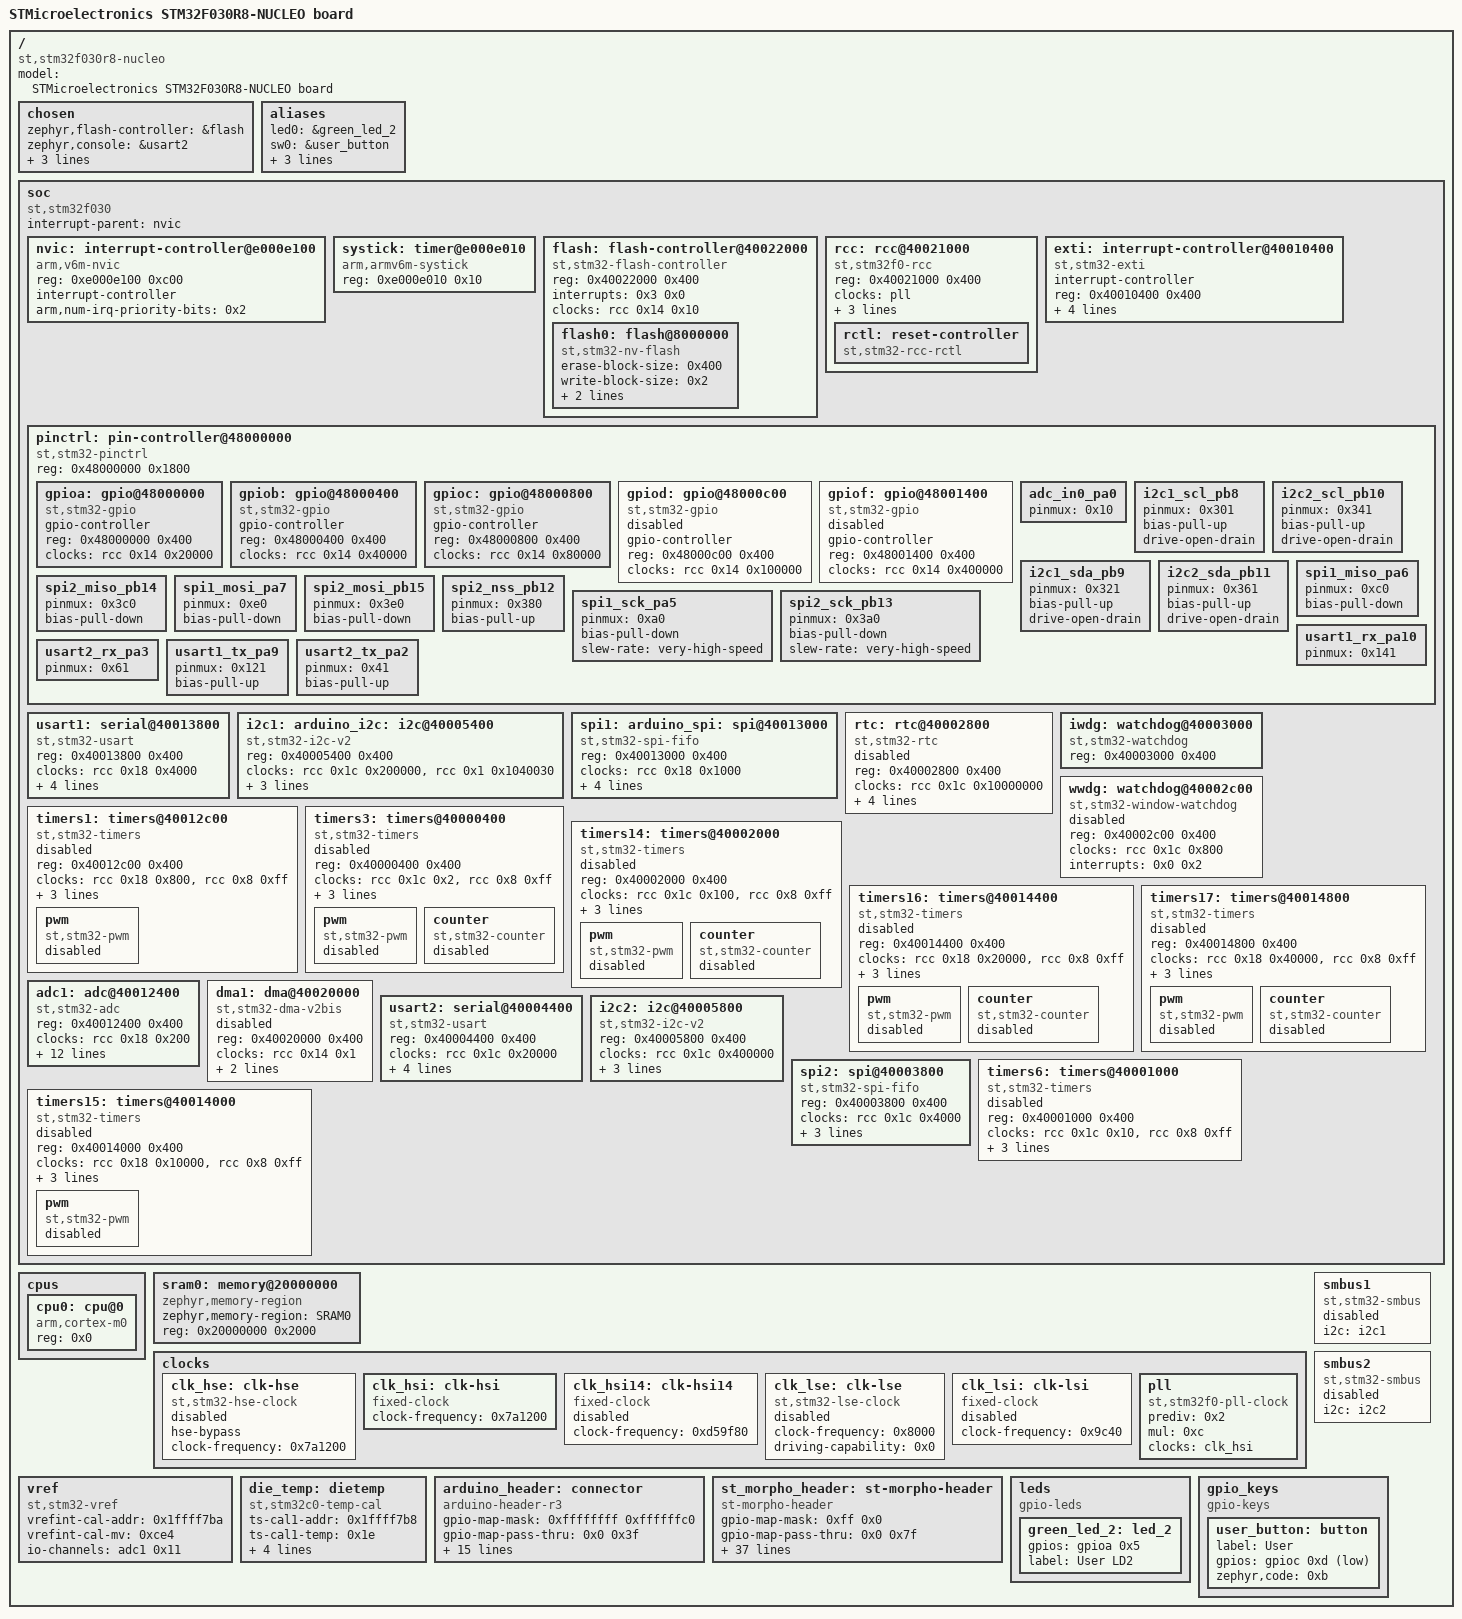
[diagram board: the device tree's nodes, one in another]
/dts-v1/;

/* node '/' defined in zephyr/dts/common/skeleton.dtsi:9 */
/ {
	#address-cells = < 0x1 >;                              /* in zephyr/dts/common/skeleton.dtsi:10 */
	#size-cells = < 0x1 >;                                 /* in zephyr/dts/common/skeleton.dtsi:11 */
	model = "STMicroelectronics STM32F030R8-NUCLEO board"; /* in zephyr/boards/st/nucleo_f030r8/nucleo_f030r8.dts:15 */
	compatible = "st,stm32f030r8-nucleo";                  /* in zephyr/boards/st/nucleo_f030r8/nucleo_f030r8.dts:16 */

	/* node '/chosen' defined in zephyr/dts/common/skeleton.dtsi:13 */
	chosen {
		zephyr,flash-controller = &flash; /* in zephyr/dts/arm/st/f0/stm32f0.dtsi:24 */
		zephyr,console = &usart2;         /* in zephyr/boards/st/nucleo_f030r8/nucleo_f030r8.dts:19 */
		zephyr,shell-uart = &usart2;      /* in zephyr/boards/st/nucleo_f030r8/nucleo_f030r8.dts:20 */
		zephyr,sram = &sram0;             /* in zephyr/boards/st/nucleo_f030r8/nucleo_f030r8.dts:21 */
		zephyr,flash = &flash0;           /* in zephyr/boards/st/nucleo_f030r8/nucleo_f030r8.dts:22 */
	};

	/* node '/aliases' defined in zephyr/dts/common/skeleton.dtsi:15 */
	aliases {
		led0 = &green_led_2;   /* in zephyr/boards/st/nucleo_f030r8/nucleo_f030r8.dts:45 */
		sw0 = &user_button;    /* in zephyr/boards/st/nucleo_f030r8/nucleo_f030r8.dts:46 */
		watchdog0 = &iwdg;     /* in zephyr/boards/st/nucleo_f030r8/nucleo_f030r8.dts:47 */
		die-temp0 = &die_temp; /* in zephyr/boards/st/nucleo_f030r8/nucleo_f030r8.dts:48 */
		volt-sensor0 = &vref;  /* in zephyr/boards/st/nucleo_f030r8/nucleo_f030r8.dts:49 */
	};

	/* node '/soc' defined in zephyr/dts/arm/armv6-m.dtsi:6 */
	soc {
		#address-cells = < 0x1 >;     /* in zephyr/dts/arm/armv6-m.dtsi:7 */
		#size-cells = < 0x1 >;        /* in zephyr/dts/arm/armv6-m.dtsi:8 */
		interrupt-parent = < &nvic >; /* in zephyr/dts/arm/armv6-m.dtsi:10 */
		ranges;                       /* in zephyr/dts/arm/armv6-m.dtsi:11 */
		compatible = "st,stm32f030",
		             "st,stm32f0",
		             "simple-bus";    /* in zephyr/dts/arm/st/f0/stm32f030.dtsi:11 */

		/* node '/soc/interrupt-controller@e000e100' defined in zephyr/dts/arm/armv6-m.dtsi:13 */
		nvic: interrupt-controller@e000e100 {
			#address-cells = < 0x1 >;            /* in zephyr/dts/arm/armv6-m.dtsi:14 */
			compatible = "arm,v6m-nvic";         /* in zephyr/dts/arm/armv6-m.dtsi:15 */
			reg = < 0xe000e100 0xc00 >;          /* in zephyr/dts/arm/armv6-m.dtsi:16 */
			interrupt-controller;                /* in zephyr/dts/arm/armv6-m.dtsi:17 */
			#interrupt-cells = < 0x2 >;          /* in zephyr/dts/arm/armv6-m.dtsi:18 */
			arm,num-irq-priority-bits = < 0x2 >; /* in zephyr/dts/arm/st/f0/stm32f0.dtsi:393 */
			phandle = < 0x1 >;                   /* in zephyr/dts/arm/armv6-m.dtsi:10 */
		};

		/* node '/soc/timer@e000e010' defined in zephyr/dts/arm/armv6-m.dtsi:21 */
		systick: timer@e000e010 {
			compatible = "arm,armv6m-systick"; /* in zephyr/dts/arm/armv6-m.dtsi:22 */
			reg = < 0xe000e010 0x10 >;         /* in zephyr/dts/arm/armv6-m.dtsi:23 */
		};

		/* node '/soc/flash-controller@40022000' defined in zephyr/dts/arm/st/f0/stm32f0.dtsi:87 */
		flash: flash-controller@40022000 {
			compatible = "st,stm32-flash-controller",
			             "st,stm32f1-flash-controller"; /* in zephyr/dts/arm/st/f0/stm32f0.dtsi:88 */
			reg = < 0x40022000 0x400 >;                 /* in zephyr/dts/arm/st/f0/stm32f0.dtsi:89 */
			interrupts = < 0x3 0x0 >;                   /* in zephyr/dts/arm/st/f0/stm32f0.dtsi:90 */
			clocks = < &rcc 0x14 0x10 >;                /* in zephyr/dts/arm/st/f0/stm32f0.dtsi:91 */
			#address-cells = < 0x1 >;                   /* in zephyr/dts/arm/st/f0/stm32f0.dtsi:93 */
			#size-cells = < 0x1 >;                      /* in zephyr/dts/arm/st/f0/stm32f0.dtsi:94 */

			/* node '/soc/flash-controller@40022000/flash@8000000' defined in zephyr/dts/arm/st/f0/stm32f0.dtsi:96 */
			flash0: flash@8000000 {
				compatible = "st,stm32-nv-flash",
				             "soc-nv-flash";      /* in zephyr/dts/arm/st/f0/stm32f0.dtsi:97 */
				erase-block-size = < 0x400 >;     /* in zephyr/dts/arm/st/f0/stm32f0.dtsi:98 */
				write-block-size = < 0x2 >;       /* in zephyr/dts/arm/st/f0/stm32f0.dtsi:99 */
				max-erase-time = < 0x28 >;        /* in zephyr/dts/arm/st/f0/stm32f0.dtsi:101 */
				reg = < 0x8000000 0x10000 >;      /* in zephyr/dts/arm/st/f0/stm32f030X8.dtsi:16 */
			};
		};

		/* node '/soc/rcc@40021000' defined in zephyr/dts/arm/st/f0/stm32f0.dtsi:105 */
		rcc: rcc@40021000 {
			compatible = "st,stm32f0-rcc";   /* in zephyr/dts/arm/st/f0/stm32f0.dtsi:106 */
			#clock-cells = < 0x2 >;          /* in zephyr/dts/arm/st/f0/stm32f0.dtsi:107 */
			reg = < 0x40021000 0x400 >;      /* in zephyr/dts/arm/st/f0/stm32f0.dtsi:108 */
			clocks = < &pll >;               /* in zephyr/boards/st/nucleo_f030r8/nucleo_f030r8.dts:67 */
			clock-frequency = < 0x2dc6c00 >; /* in zephyr/boards/st/nucleo_f030r8/nucleo_f030r8.dts:68 */
			ahb-prescaler = < 0x1 >;         /* in zephyr/boards/st/nucleo_f030r8/nucleo_f030r8.dts:69 */
			apb1-prescaler = < 0x1 >;        /* in zephyr/boards/st/nucleo_f030r8/nucleo_f030r8.dts:70 */
			phandle = < 0x2 >;               /* in zephyr/dts/arm/st/f0/stm32f0.dtsi:91 */

			/* node '/soc/rcc@40021000/reset-controller' defined in zephyr/dts/arm/st/f0/stm32f0.dtsi:110 */
			rctl: reset-controller {
				compatible = "st,stm32-rcc-rctl"; /* in zephyr/dts/arm/st/f0/stm32f0.dtsi:111 */
				#reset-cells = < 0x1 >;           /* in zephyr/dts/arm/st/f0/stm32f0.dtsi:112 */
				phandle = < 0x4 >;                /* in zephyr/dts/arm/st/f0/stm32f0.dtsi:180 */
			};
		};

		/* node '/soc/interrupt-controller@40010400' defined in zephyr/dts/arm/st/f0/stm32f0.dtsi:116 */
		exti: interrupt-controller@40010400 {
			compatible = "st,stm32-exti"; /* in zephyr/dts/arm/st/f0/stm32f0.dtsi:117 */
			interrupt-controller;         /* in zephyr/dts/arm/st/f0/stm32f0.dtsi:118 */
			#interrupt-cells = < 0x1 >;   /* in zephyr/dts/arm/st/f0/stm32f0.dtsi:119 */
			#address-cells = < 0x0 >;     /* in zephyr/dts/arm/st/f0/stm32f0.dtsi:120 */
			reg = < 0x40010400 0x400 >;   /* in zephyr/dts/arm/st/f0/stm32f0.dtsi:121 */
			clocks = < &rcc 0x18 0x1 >;   /* in zephyr/dts/arm/st/f0/stm32f0.dtsi:122 */
			num-lines = < 0x20 >;         /* in zephyr/dts/arm/st/f0/stm32f0.dtsi:123 */
			interrupts = < 0x5 0x0 >,
			             < 0x6 0x0 >,
			             < 0x7 0x0 >;     /* in zephyr/dts/arm/st/f0/stm32f0.dtsi:124 */
			interrupt-names = "line0-1",
			                  "line2-3",
			                  "line4-15"; /* in zephyr/dts/arm/st/f0/stm32f0.dtsi:125 */
			line-ranges = < 0x0 0x2 >,
			              < 0x2 0x2 >,
			              < 0x4 0xc >;    /* in zephyr/dts/arm/st/f0/stm32f0.dtsi:126 */
		};

		/* node '/soc/pin-controller@48000000' defined in zephyr/dts/arm/st/f0/stm32f0.dtsi:129 */
		pinctrl: pin-controller@48000000 {
			compatible = "st,stm32-pinctrl"; /* in zephyr/dts/arm/st/f0/stm32f0.dtsi:130 */
			#address-cells = < 0x1 >;        /* in zephyr/dts/arm/st/f0/stm32f0.dtsi:131 */
			#size-cells = < 0x1 >;           /* in zephyr/dts/arm/st/f0/stm32f0.dtsi:132 */
			reg = < 0x48000000 0x1800 >;     /* in zephyr/dts/arm/st/f0/stm32f0.dtsi:133 */

			/* node '/soc/pin-controller@48000000/gpio@48000000' defined in zephyr/dts/arm/st/f0/stm32f0.dtsi:135 */
			gpioa: gpio@48000000 {
				compatible = "st,stm32-gpio";   /* in zephyr/dts/arm/st/f0/stm32f0.dtsi:136 */
				gpio-controller;                /* in zephyr/dts/arm/st/f0/stm32f0.dtsi:137 */
				#gpio-cells = < 0x2 >;          /* in zephyr/dts/arm/st/f0/stm32f0.dtsi:138 */
				reg = < 0x48000000 0x400 >;     /* in zephyr/dts/arm/st/f0/stm32f0.dtsi:139 */
				clocks = < &rcc 0x14 0x20000 >; /* in zephyr/dts/arm/st/f0/stm32f0.dtsi:140 */
				phandle = < 0x1a >;             /* in zephyr/boards/st/nucleo_f030r8/arduino_r3_connector.dtsi:15 */
			};

			/* node '/soc/pin-controller@48000000/gpio@48000400' defined in zephyr/dts/arm/st/f0/stm32f0.dtsi:143 */
			gpiob: gpio@48000400 {
				compatible = "st,stm32-gpio";   /* in zephyr/dts/arm/st/f0/stm32f0.dtsi:144 */
				gpio-controller;                /* in zephyr/dts/arm/st/f0/stm32f0.dtsi:145 */
				#gpio-cells = < 0x2 >;          /* in zephyr/dts/arm/st/f0/stm32f0.dtsi:146 */
				reg = < 0x48000400 0x400 >;     /* in zephyr/dts/arm/st/f0/stm32f0.dtsi:147 */
				clocks = < &rcc 0x14 0x40000 >; /* in zephyr/dts/arm/st/f0/stm32f0.dtsi:148 */
				phandle = < 0xc >;              /* in zephyr/boards/st/nucleo_f030r8/nucleo_f030r8.dts:114 */
			};

			/* node '/soc/pin-controller@48000000/gpio@48000800' defined in zephyr/dts/arm/st/f0/stm32f0.dtsi:151 */
			gpioc: gpio@48000800 {
				compatible = "st,stm32-gpio";   /* in zephyr/dts/arm/st/f0/stm32f0.dtsi:152 */
				gpio-controller;                /* in zephyr/dts/arm/st/f0/stm32f0.dtsi:153 */
				#gpio-cells = < 0x2 >;          /* in zephyr/dts/arm/st/f0/stm32f0.dtsi:154 */
				reg = < 0x48000800 0x400 >;     /* in zephyr/dts/arm/st/f0/stm32f0.dtsi:155 */
				clocks = < &rcc 0x14 0x80000 >; /* in zephyr/dts/arm/st/f0/stm32f0.dtsi:156 */
				phandle = < 0x1b >;             /* in zephyr/boards/st/nucleo_f030r8/arduino_r3_connector.dtsi:15 */
			};

			/* node '/soc/pin-controller@48000000/gpio@48000c00' defined in zephyr/dts/arm/st/f0/stm32f0.dtsi:159 */
			gpiod: gpio@48000c00 {
				compatible = "st,stm32-gpio";    /* in zephyr/dts/arm/st/f0/stm32f0.dtsi:160 */
				gpio-controller;                 /* in zephyr/dts/arm/st/f0/stm32f0.dtsi:161 */
				#gpio-cells = < 0x2 >;           /* in zephyr/dts/arm/st/f0/stm32f0.dtsi:162 */
				reg = < 0x48000c00 0x400 >;      /* in zephyr/dts/arm/st/f0/stm32f0.dtsi:163 */
				clocks = < &rcc 0x14 0x100000 >; /* in zephyr/dts/arm/st/f0/stm32f0.dtsi:164 */
				status = "disabled";             /* in zephyr/boards/st/nucleo_f030r8/nucleo_f030r8.dts:76 */
				phandle = < 0x1c >;              /* in zephyr/boards/st/nucleo_f030r8/st_morpho_connector.dtsi:15 */
			};

			/* node '/soc/pin-controller@48000000/gpio@48001400' defined in zephyr/dts/arm/st/f0/stm32f0.dtsi:167 */
			gpiof: gpio@48001400 {
				compatible = "st,stm32-gpio";    /* in zephyr/dts/arm/st/f0/stm32f0.dtsi:168 */
				gpio-controller;                 /* in zephyr/dts/arm/st/f0/stm32f0.dtsi:169 */
				#gpio-cells = < 0x2 >;           /* in zephyr/dts/arm/st/f0/stm32f0.dtsi:170 */
				reg = < 0x48001400 0x400 >;      /* in zephyr/dts/arm/st/f0/stm32f0.dtsi:171 */
				clocks = < &rcc 0x14 0x400000 >; /* in zephyr/dts/arm/st/f0/stm32f0.dtsi:172 */
				status = "disabled";             /* in zephyr/boards/st/nucleo_f030r8/nucleo_f030r8.dts:80 */
				phandle = < 0x1d >;              /* in zephyr/boards/st/nucleo_f030r8/st_morpho_connector.dtsi:15 */
			};

			/* node '/soc/pin-controller@48000000/adc_in0_pa0' defined in modules/hal/stm32/dts/st/f0/stm32f030r8tx-pinctrl.dtsi:15 */
			adc_in0_pa0: adc_in0_pa0 {
				pinmux = < 0x10 >; /* in modules/hal/stm32/dts/st/f0/stm32f030r8tx-pinctrl.dtsi:16 */
				phandle = < 0xd >; /* in zephyr/boards/st/nucleo_f030r8/nucleo_f030r8.dts:126 */
			};

			/* node '/soc/pin-controller@48000000/i2c1_scl_pb8' defined in modules/hal/stm32/dts/st/f0/stm32f030r8tx-pinctrl.dtsi:309 */
			i2c1_scl_pb8: i2c1_scl_pb8 {
				pinmux = < 0x301 >; /* in modules/hal/stm32/dts/st/f0/stm32f030r8tx-pinctrl.dtsi:310 */
				bias-pull-up;       /* in modules/hal/stm32/dts/st/f0/stm32f030r8tx-pinctrl.dtsi:311 */
				drive-open-drain;   /* in modules/hal/stm32/dts/st/f0/stm32f030r8tx-pinctrl.dtsi:312 */
				phandle = < 0x7 >;  /* in zephyr/boards/st/nucleo_f030r8/nucleo_f030r8.dts:98 */
			};

			/* node '/soc/pin-controller@48000000/i2c2_scl_pb10' defined in modules/hal/stm32/dts/st/f0/stm32f030r8tx-pinctrl.dtsi:315 */
			i2c2_scl_pb10: i2c2_scl_pb10 {
				pinmux = < 0x341 >; /* in modules/hal/stm32/dts/st/f0/stm32f030r8tx-pinctrl.dtsi:316 */
				bias-pull-up;       /* in modules/hal/stm32/dts/st/f0/stm32f030r8tx-pinctrl.dtsi:317 */
				drive-open-drain;   /* in modules/hal/stm32/dts/st/f0/stm32f030r8tx-pinctrl.dtsi:318 */
				phandle = < 0x10 >; /* in zephyr/boards/st/nucleo_f030r8/nucleo_f030r8.dts:105 */
			};

			/* node '/soc/pin-controller@48000000/i2c1_sda_pb9' defined in modules/hal/stm32/dts/st/f0/stm32f030r8tx-pinctrl.dtsi:335 */
			i2c1_sda_pb9: i2c1_sda_pb9 {
				pinmux = < 0x321 >; /* in modules/hal/stm32/dts/st/f0/stm32f030r8tx-pinctrl.dtsi:336 */
				bias-pull-up;       /* in modules/hal/stm32/dts/st/f0/stm32f030r8tx-pinctrl.dtsi:337 */
				drive-open-drain;   /* in modules/hal/stm32/dts/st/f0/stm32f030r8tx-pinctrl.dtsi:338 */
				phandle = < 0x8 >;  /* in zephyr/boards/st/nucleo_f030r8/nucleo_f030r8.dts:98 */
			};

			/* node '/soc/pin-controller@48000000/i2c2_sda_pb11' defined in modules/hal/stm32/dts/st/f0/stm32f030r8tx-pinctrl.dtsi:341 */
			i2c2_sda_pb11: i2c2_sda_pb11 {
				pinmux = < 0x361 >; /* in modules/hal/stm32/dts/st/f0/stm32f030r8tx-pinctrl.dtsi:342 */
				bias-pull-up;       /* in modules/hal/stm32/dts/st/f0/stm32f030r8tx-pinctrl.dtsi:343 */
				drive-open-drain;   /* in modules/hal/stm32/dts/st/f0/stm32f030r8tx-pinctrl.dtsi:344 */
				phandle = < 0x11 >; /* in zephyr/boards/st/nucleo_f030r8/nucleo_f030r8.dts:105 */
			};

			/* node '/soc/pin-controller@48000000/spi1_miso_pa6' defined in modules/hal/stm32/dts/st/f0/stm32f030r8tx-pinctrl.dtsi:379 */
			spi1_miso_pa6: spi1_miso_pa6 {
				pinmux = < 0xc0 >; /* in modules/hal/stm32/dts/st/f0/stm32f030r8tx-pinctrl.dtsi:380 */
				bias-pull-down;    /* in modules/hal/stm32/dts/st/f0/stm32f030r8tx-pinctrl.dtsi:381 */
				phandle = < 0xa >; /* in zephyr/boards/st/nucleo_f030r8/nucleo_f030r8.dts:112 */
			};

			/* node '/soc/pin-controller@48000000/spi2_miso_pb14' defined in modules/hal/stm32/dts/st/f0/stm32f030r8tx-pinctrl.dtsi:389 */
			spi2_miso_pb14: spi2_miso_pb14 {
				pinmux = < 0x3c0 >; /* in modules/hal/stm32/dts/st/f0/stm32f030r8tx-pinctrl.dtsi:390 */
				bias-pull-down;     /* in modules/hal/stm32/dts/st/f0/stm32f030r8tx-pinctrl.dtsi:391 */
				phandle = < 0x14 >; /* in zephyr/boards/st/nucleo_f030r8/nucleo_f030r8.dts:119 */
			};

			/* node '/soc/pin-controller@48000000/spi1_mosi_pa7' defined in modules/hal/stm32/dts/st/f0/stm32f030r8tx-pinctrl.dtsi:396 */
			spi1_mosi_pa7: spi1_mosi_pa7 {
				pinmux = < 0xe0 >; /* in modules/hal/stm32/dts/st/f0/stm32f030r8tx-pinctrl.dtsi:397 */
				bias-pull-down;    /* in modules/hal/stm32/dts/st/f0/stm32f030r8tx-pinctrl.dtsi:398 */
				phandle = < 0xb >; /* in zephyr/boards/st/nucleo_f030r8/nucleo_f030r8.dts:112 */
			};

			/* node '/soc/pin-controller@48000000/spi2_mosi_pb15' defined in modules/hal/stm32/dts/st/f0/stm32f030r8tx-pinctrl.dtsi:406 */
			spi2_mosi_pb15: spi2_mosi_pb15 {
				pinmux = < 0x3e0 >; /* in modules/hal/stm32/dts/st/f0/stm32f030r8tx-pinctrl.dtsi:407 */
				bias-pull-down;     /* in modules/hal/stm32/dts/st/f0/stm32f030r8tx-pinctrl.dtsi:408 */
				phandle = < 0x15 >; /* in zephyr/boards/st/nucleo_f030r8/nucleo_f030r8.dts:119 */
			};

			/* node '/soc/pin-controller@48000000/spi2_nss_pb12' defined in modules/hal/stm32/dts/st/f0/stm32f030r8tx-pinctrl.dtsi:423 */
			spi2_nss_pb12: spi2_nss_pb12 {
				pinmux = < 0x380 >; /* in modules/hal/stm32/dts/st/f0/stm32f030r8tx-pinctrl.dtsi:424 */
				bias-pull-up;       /* in modules/hal/stm32/dts/st/f0/stm32f030r8tx-pinctrl.dtsi:425 */
				phandle = < 0x12 >; /* in zephyr/boards/st/nucleo_f030r8/nucleo_f030r8.dts:119 */
			};

			/* node '/soc/pin-controller@48000000/spi1_sck_pa5' defined in modules/hal/stm32/dts/st/f0/stm32f030r8tx-pinctrl.dtsi:430 */
			spi1_sck_pa5: spi1_sck_pa5 {
				pinmux = < 0xa0 >;             /* in modules/hal/stm32/dts/st/f0/stm32f030r8tx-pinctrl.dtsi:431 */
				bias-pull-down;                /* in modules/hal/stm32/dts/st/f0/stm32f030r8tx-pinctrl.dtsi:432 */
				slew-rate = "very-high-speed"; /* in modules/hal/stm32/dts/st/f0/stm32f030r8tx-pinctrl.dtsi:433 */
				phandle = < 0x9 >;             /* in zephyr/boards/st/nucleo_f030r8/nucleo_f030r8.dts:112 */
			};

			/* node '/soc/pin-controller@48000000/spi2_sck_pb13' defined in modules/hal/stm32/dts/st/f0/stm32f030r8tx-pinctrl.dtsi:442 */
			spi2_sck_pb13: spi2_sck_pb13 {
				pinmux = < 0x3a0 >;            /* in modules/hal/stm32/dts/st/f0/stm32f030r8tx-pinctrl.dtsi:443 */
				bias-pull-down;                /* in modules/hal/stm32/dts/st/f0/stm32f030r8tx-pinctrl.dtsi:444 */
				slew-rate = "very-high-speed"; /* in modules/hal/stm32/dts/st/f0/stm32f030r8tx-pinctrl.dtsi:445 */
				phandle = < 0x13 >;            /* in zephyr/boards/st/nucleo_f030r8/nucleo_f030r8.dts:119 */
			};

			/* node '/soc/pin-controller@48000000/usart1_rx_pa10' defined in modules/hal/stm32/dts/st/f0/stm32f030r8tx-pinctrl.dtsi:646 */
			usart1_rx_pa10: usart1_rx_pa10 {
				pinmux = < 0x141 >; /* in modules/hal/stm32/dts/st/f0/stm32f030r8tx-pinctrl.dtsi:647 */
				phandle = < 0x6 >;  /* in zephyr/boards/st/nucleo_f030r8/nucleo_f030r8.dts:84 */
			};

			/* node '/soc/pin-controller@48000000/usart2_rx_pa3' defined in modules/hal/stm32/dts/st/f0/stm32f030r8tx-pinctrl.dtsi:654 */
			usart2_rx_pa3: usart2_rx_pa3 {
				pinmux = < 0x61 >; /* in modules/hal/stm32/dts/st/f0/stm32f030r8tx-pinctrl.dtsi:655 */
				phandle = < 0xf >; /* in zephyr/boards/st/nucleo_f030r8/nucleo_f030r8.dts:91 */
			};

			/* node '/soc/pin-controller@48000000/usart1_tx_pa9' defined in modules/hal/stm32/dts/st/f0/stm32f030r8tx-pinctrl.dtsi:664 */
			usart1_tx_pa9: usart1_tx_pa9 {
				pinmux = < 0x121 >; /* in modules/hal/stm32/dts/st/f0/stm32f030r8tx-pinctrl.dtsi:665 */
				bias-pull-up;       /* in modules/hal/stm32/dts/st/f0/stm32f030r8tx-pinctrl.dtsi:666 */
				phandle = < 0x5 >;  /* in zephyr/boards/st/nucleo_f030r8/nucleo_f030r8.dts:84 */
			};

			/* node '/soc/pin-controller@48000000/usart2_tx_pa2' defined in modules/hal/stm32/dts/st/f0/stm32f030r8tx-pinctrl.dtsi:674 */
			usart2_tx_pa2: usart2_tx_pa2 {
				pinmux = < 0x41 >; /* in modules/hal/stm32/dts/st/f0/stm32f030r8tx-pinctrl.dtsi:675 */
				bias-pull-up;      /* in modules/hal/stm32/dts/st/f0/stm32f030r8tx-pinctrl.dtsi:676 */
				phandle = < 0xe >; /* in zephyr/boards/st/nucleo_f030r8/nucleo_f030r8.dts:91 */
			};
		};

		/* node '/soc/serial@40013800' defined in zephyr/dts/arm/st/f0/stm32f0.dtsi:176 */
		usart1: serial@40013800 {
			compatible = "st,stm32-usart",
			             "st,stm32-uart";                   /* in zephyr/dts/arm/st/f0/stm32f0.dtsi:177 */
			reg = < 0x40013800 0x400 >;                     /* in zephyr/dts/arm/st/f0/stm32f0.dtsi:178 */
			clocks = < &rcc 0x18 0x4000 >;                  /* in zephyr/dts/arm/st/f0/stm32f0.dtsi:179 */
			resets = < &rctl 0x18e >;                       /* in zephyr/dts/arm/st/f0/stm32f0.dtsi:180 */
			interrupts = < 0x1b 0x0 >;                      /* in zephyr/dts/arm/st/f0/stm32f0.dtsi:181 */
			pinctrl-0 = < &usart1_tx_pa9 &usart1_rx_pa10 >; /* in zephyr/boards/st/nucleo_f030r8/nucleo_f030r8.dts:84 */
			pinctrl-names = "default";                      /* in zephyr/boards/st/nucleo_f030r8/nucleo_f030r8.dts:85 */
			current-speed = < 0x1c200 >;                    /* in zephyr/boards/st/nucleo_f030r8/nucleo_f030r8.dts:86 */
			status = "okay";                                /* in zephyr/boards/st/nucleo_f030r8/nucleo_f030r8.dts:87 */
		};

		/* node '/soc/i2c@40005400' defined in zephyr/dts/arm/st/f0/stm32f0.dtsi:185 */
		i2c1: arduino_i2c: i2c@40005400 {
			compatible = "st,stm32-i2c-v2";              /* in zephyr/dts/arm/st/f0/stm32f0.dtsi:186 */
			#address-cells = < 0x1 >;                    /* in zephyr/dts/arm/st/f0/stm32f0.dtsi:188 */
			#size-cells = < 0x0 >;                       /* in zephyr/dts/arm/st/f0/stm32f0.dtsi:189 */
			reg = < 0x40005400 0x400 >;                  /* in zephyr/dts/arm/st/f0/stm32f0.dtsi:190 */
			clocks = < &rcc 0x1c 0x200000 >,
			         < &rcc 0x1 0x1040030 >;             /* in zephyr/dts/arm/st/f0/stm32f0.dtsi:191 */
			interrupts = < 0x17 0x0 >;                   /* in zephyr/dts/arm/st/f0/stm32f0.dtsi:196 */
			interrupt-names = "combined";                /* in zephyr/dts/arm/st/f0/stm32f0.dtsi:197 */
			pinctrl-0 = < &i2c1_scl_pb8 &i2c1_sda_pb9 >; /* in zephyr/boards/st/nucleo_f030r8/nucleo_f030r8.dts:98 */
			pinctrl-names = "default";                   /* in zephyr/boards/st/nucleo_f030r8/nucleo_f030r8.dts:99 */
			status = "okay";                             /* in zephyr/boards/st/nucleo_f030r8/nucleo_f030r8.dts:100 */
			clock-frequency = < 0x61a80 >;               /* in zephyr/boards/st/nucleo_f030r8/nucleo_f030r8.dts:101 */
			phandle = < 0x18 >;                          /* in zephyr/dts/arm/st/f0/stm32f0.dtsi:387 */
		};

		/* node '/soc/spi@40013000' defined in zephyr/dts/arm/st/f0/stm32f0.dtsi:201 */
		spi1: arduino_spi: spi@40013000 {
			compatible = "st,stm32-spi-fifo",
			             "st,stm32-spi";                                 /* in zephyr/dts/arm/st/f0/stm32f0.dtsi:202 */
			#address-cells = < 0x1 >;                                    /* in zephyr/dts/arm/st/f0/stm32f0.dtsi:203 */
			#size-cells = < 0x0 >;                                       /* in zephyr/dts/arm/st/f0/stm32f0.dtsi:204 */
			reg = < 0x40013000 0x400 >;                                  /* in zephyr/dts/arm/st/f0/stm32f0.dtsi:205 */
			clocks = < &rcc 0x18 0x1000 >;                               /* in zephyr/dts/arm/st/f0/stm32f0.dtsi:206 */
			interrupts = < 0x19 0x3 >;                                   /* in zephyr/dts/arm/st/f0/stm32f0.dtsi:207 */
			pinctrl-0 = < &spi1_sck_pa5 &spi1_miso_pa6 &spi1_mosi_pa7 >; /* in zephyr/boards/st/nucleo_f030r8/nucleo_f030r8.dts:112 */
			pinctrl-names = "default";                                   /* in zephyr/boards/st/nucleo_f030r8/nucleo_f030r8.dts:113 */
			cs-gpios = < &gpiob 0x6 0x11 >;                              /* in zephyr/boards/st/nucleo_f030r8/nucleo_f030r8.dts:114 */
			status = "okay";                                             /* in zephyr/boards/st/nucleo_f030r8/nucleo_f030r8.dts:115 */
		};

		/* node '/soc/rtc@40002800' defined in zephyr/dts/arm/st/f0/stm32f0.dtsi:211 */
		rtc: rtc@40002800 {
			compatible = "st,stm32-rtc";       /* in zephyr/dts/arm/st/f0/stm32f0.dtsi:212 */
			reg = < 0x40002800 0x400 >;        /* in zephyr/dts/arm/st/f0/stm32f0.dtsi:213 */
			clocks = < &rcc 0x1c 0x10000000 >; /* in zephyr/dts/arm/st/f0/stm32f0.dtsi:214 */
			interrupts = < 0x2 0x0 >;          /* in zephyr/dts/arm/st/f0/stm32f0.dtsi:215 */
			prescaler = < 0x8000 >;            /* in zephyr/dts/arm/st/f0/stm32f0.dtsi:216 */
			alarms-count = < 0x1 >;            /* in zephyr/dts/arm/st/f0/stm32f0.dtsi:217 */
			alrm-exti-line = < 0x11 >;         /* in zephyr/dts/arm/st/f0/stm32f0.dtsi:218 */
			status = "disabled";               /* in zephyr/dts/arm/st/f0/stm32f0.dtsi:219 */
		};

		/* node '/soc/watchdog@40003000' defined in zephyr/dts/arm/st/f0/stm32f0.dtsi:222 */
		iwdg: watchdog@40003000 {
			compatible = "st,stm32-watchdog"; /* in zephyr/dts/arm/st/f0/stm32f0.dtsi:223 */
			reg = < 0x40003000 0x400 >;       /* in zephyr/dts/arm/st/f0/stm32f0.dtsi:224 */
			status = "okay";                  /* in zephyr/boards/st/nucleo_f030r8/nucleo_f030r8.dts:134 */
		};

		/* node '/soc/watchdog@40002c00' defined in zephyr/dts/arm/st/f0/stm32f0.dtsi:228 */
		wwdg: watchdog@40002c00 {
			compatible = "st,stm32-window-watchdog"; /* in zephyr/dts/arm/st/f0/stm32f0.dtsi:229 */
			reg = < 0x40002c00 0x400 >;              /* in zephyr/dts/arm/st/f0/stm32f0.dtsi:230 */
			clocks = < &rcc 0x1c 0x800 >;            /* in zephyr/dts/arm/st/f0/stm32f0.dtsi:231 */
			interrupts = < 0x0 0x2 >;                /* in zephyr/dts/arm/st/f0/stm32f0.dtsi:232 */
			status = "disabled";                     /* in zephyr/dts/arm/st/f0/stm32f0.dtsi:233 */
		};

		/* node '/soc/timers@40012c00' defined in zephyr/dts/arm/st/f0/stm32f0.dtsi:236 */
		timers1: timers@40012c00 {
			compatible = "st,stm32-timers";     /* in zephyr/dts/arm/st/f0/stm32f0.dtsi:237 */
			reg = < 0x40012c00 0x400 >;         /* in zephyr/dts/arm/st/f0/stm32f0.dtsi:238 */
			clocks = < &rcc 0x18 0x800 >,
			         < &rcc 0x8 0xff >;         /* in zephyr/dts/arm/st/f0/stm32f0.dtsi:239 */
			resets = < &rctl 0x18b >;           /* in zephyr/dts/arm/st/f0/stm32f0.dtsi:241 */
			interrupts = < 0xd 0x0 >,
			             < 0xe 0x0 >;           /* in zephyr/dts/arm/st/f0/stm32f0.dtsi:242 */
			interrupt-names = "brk_up_trg_com",
			                  "cc";             /* in zephyr/dts/arm/st/f0/stm32f0.dtsi:243 */
			st,prescaler = < 0x0 >;             /* in zephyr/dts/arm/st/f0/stm32f0.dtsi:244 */
			status = "disabled";                /* in zephyr/dts/arm/st/f0/stm32f0.dtsi:245 */

			/* node '/soc/timers@40012c00/pwm' defined in zephyr/dts/arm/st/f0/stm32f0.dtsi:247 */
			pwm {
				compatible = "st,stm32-pwm"; /* in zephyr/dts/arm/st/f0/stm32f0.dtsi:248 */
				status = "disabled";         /* in zephyr/dts/arm/st/f0/stm32f0.dtsi:249 */
				#pwm-cells = < 0x3 >;        /* in zephyr/dts/arm/st/f0/stm32f0.dtsi:250 */
			};
		};

		/* node '/soc/timers@40000400' defined in zephyr/dts/arm/st/f0/stm32f0.dtsi:254 */
		timers3: timers@40000400 {
			compatible = "st,stm32-timers"; /* in zephyr/dts/arm/st/f0/stm32f0.dtsi:255 */
			reg = < 0x40000400 0x400 >;     /* in zephyr/dts/arm/st/f0/stm32f0.dtsi:256 */
			clocks = < &rcc 0x1c 0x2 >,
			         < &rcc 0x8 0xff >;     /* in zephyr/dts/arm/st/f0/stm32f0.dtsi:257 */
			resets = < &rctl 0x201 >;       /* in zephyr/dts/arm/st/f0/stm32f0.dtsi:259 */
			interrupts = < 0x10 0x0 >;      /* in zephyr/dts/arm/st/f0/stm32f0.dtsi:260 */
			interrupt-names = "global";     /* in zephyr/dts/arm/st/f0/stm32f0.dtsi:261 */
			st,prescaler = < 0x0 >;         /* in zephyr/dts/arm/st/f0/stm32f0.dtsi:262 */
			status = "disabled";            /* in zephyr/dts/arm/st/f0/stm32f0.dtsi:263 */

			/* node '/soc/timers@40000400/pwm' defined in zephyr/dts/arm/st/f0/stm32f0.dtsi:265 */
			pwm {
				compatible = "st,stm32-pwm"; /* in zephyr/dts/arm/st/f0/stm32f0.dtsi:266 */
				status = "disabled";         /* in zephyr/dts/arm/st/f0/stm32f0.dtsi:267 */
				#pwm-cells = < 0x3 >;        /* in zephyr/dts/arm/st/f0/stm32f0.dtsi:268 */
			};

			/* node '/soc/timers@40000400/counter' defined in zephyr/dts/arm/st/f0/stm32f0.dtsi:271 */
			counter {
				compatible = "st,stm32-counter"; /* in zephyr/dts/arm/st/f0/stm32f0.dtsi:272 */
				status = "disabled";             /* in zephyr/dts/arm/st/f0/stm32f0.dtsi:273 */
			};
		};

		/* node '/soc/timers@40002000' defined in zephyr/dts/arm/st/f0/stm32f0.dtsi:277 */
		timers14: timers@40002000 {
			compatible = "st,stm32-timers"; /* in zephyr/dts/arm/st/f0/stm32f0.dtsi:278 */
			reg = < 0x40002000 0x400 >;     /* in zephyr/dts/arm/st/f0/stm32f0.dtsi:279 */
			clocks = < &rcc 0x1c 0x100 >,
			         < &rcc 0x8 0xff >;     /* in zephyr/dts/arm/st/f0/stm32f0.dtsi:280 */
			resets = < &rctl 0x208 >;       /* in zephyr/dts/arm/st/f0/stm32f0.dtsi:282 */
			interrupts = < 0x13 0x0 >;      /* in zephyr/dts/arm/st/f0/stm32f0.dtsi:283 */
			interrupt-names = "global";     /* in zephyr/dts/arm/st/f0/stm32f0.dtsi:284 */
			st,prescaler = < 0x0 >;         /* in zephyr/dts/arm/st/f0/stm32f0.dtsi:285 */
			status = "disabled";            /* in zephyr/dts/arm/st/f0/stm32f0.dtsi:286 */

			/* node '/soc/timers@40002000/pwm' defined in zephyr/dts/arm/st/f0/stm32f0.dtsi:288 */
			pwm {
				compatible = "st,stm32-pwm"; /* in zephyr/dts/arm/st/f0/stm32f0.dtsi:289 */
				status = "disabled";         /* in zephyr/dts/arm/st/f0/stm32f0.dtsi:290 */
				#pwm-cells = < 0x3 >;        /* in zephyr/dts/arm/st/f0/stm32f0.dtsi:291 */
			};

			/* node '/soc/timers@40002000/counter' defined in zephyr/dts/arm/st/f0/stm32f0.dtsi:294 */
			counter {
				compatible = "st,stm32-counter"; /* in zephyr/dts/arm/st/f0/stm32f0.dtsi:295 */
				status = "disabled";             /* in zephyr/dts/arm/st/f0/stm32f0.dtsi:296 */
			};
		};

		/* node '/soc/timers@40014400' defined in zephyr/dts/arm/st/f0/stm32f0.dtsi:300 */
		timers16: timers@40014400 {
			compatible = "st,stm32-timers"; /* in zephyr/dts/arm/st/f0/stm32f0.dtsi:301 */
			reg = < 0x40014400 0x400 >;     /* in zephyr/dts/arm/st/f0/stm32f0.dtsi:302 */
			clocks = < &rcc 0x18 0x20000 >,
			         < &rcc 0x8 0xff >;     /* in zephyr/dts/arm/st/f0/stm32f0.dtsi:303 */
			resets = < &rctl 0x191 >;       /* in zephyr/dts/arm/st/f0/stm32f0.dtsi:305 */
			interrupts = < 0x15 0x0 >;      /* in zephyr/dts/arm/st/f0/stm32f0.dtsi:306 */
			interrupt-names = "global";     /* in zephyr/dts/arm/st/f0/stm32f0.dtsi:307 */
			st,prescaler = < 0x0 >;         /* in zephyr/dts/arm/st/f0/stm32f0.dtsi:308 */
			status = "disabled";            /* in zephyr/dts/arm/st/f0/stm32f0.dtsi:309 */

			/* node '/soc/timers@40014400/pwm' defined in zephyr/dts/arm/st/f0/stm32f0.dtsi:311 */
			pwm {
				compatible = "st,stm32-pwm"; /* in zephyr/dts/arm/st/f0/stm32f0.dtsi:312 */
				status = "disabled";         /* in zephyr/dts/arm/st/f0/stm32f0.dtsi:313 */
				#pwm-cells = < 0x3 >;        /* in zephyr/dts/arm/st/f0/stm32f0.dtsi:314 */
			};

			/* node '/soc/timers@40014400/counter' defined in zephyr/dts/arm/st/f0/stm32f0.dtsi:317 */
			counter {
				compatible = "st,stm32-counter"; /* in zephyr/dts/arm/st/f0/stm32f0.dtsi:318 */
				status = "disabled";             /* in zephyr/dts/arm/st/f0/stm32f0.dtsi:319 */
			};
		};

		/* node '/soc/timers@40014800' defined in zephyr/dts/arm/st/f0/stm32f0.dtsi:323 */
		timers17: timers@40014800 {
			compatible = "st,stm32-timers"; /* in zephyr/dts/arm/st/f0/stm32f0.dtsi:324 */
			reg = < 0x40014800 0x400 >;     /* in zephyr/dts/arm/st/f0/stm32f0.dtsi:325 */
			clocks = < &rcc 0x18 0x40000 >,
			         < &rcc 0x8 0xff >;     /* in zephyr/dts/arm/st/f0/stm32f0.dtsi:326 */
			resets = < &rctl 0x192 >;       /* in zephyr/dts/arm/st/f0/stm32f0.dtsi:328 */
			interrupts = < 0x16 0x0 >;      /* in zephyr/dts/arm/st/f0/stm32f0.dtsi:329 */
			interrupt-names = "global";     /* in zephyr/dts/arm/st/f0/stm32f0.dtsi:330 */
			st,prescaler = < 0x0 >;         /* in zephyr/dts/arm/st/f0/stm32f0.dtsi:331 */
			status = "disabled";            /* in zephyr/dts/arm/st/f0/stm32f0.dtsi:332 */

			/* node '/soc/timers@40014800/pwm' defined in zephyr/dts/arm/st/f0/stm32f0.dtsi:334 */
			pwm {
				compatible = "st,stm32-pwm"; /* in zephyr/dts/arm/st/f0/stm32f0.dtsi:335 */
				status = "disabled";         /* in zephyr/dts/arm/st/f0/stm32f0.dtsi:336 */
				#pwm-cells = < 0x3 >;        /* in zephyr/dts/arm/st/f0/stm32f0.dtsi:337 */
			};

			/* node '/soc/timers@40014800/counter' defined in zephyr/dts/arm/st/f0/stm32f0.dtsi:340 */
			counter {
				compatible = "st,stm32-counter"; /* in zephyr/dts/arm/st/f0/stm32f0.dtsi:341 */
				status = "disabled";             /* in zephyr/dts/arm/st/f0/stm32f0.dtsi:342 */
			};
		};

		/* node '/soc/adc@40012400' defined in zephyr/dts/arm/st/f0/stm32f0.dtsi:346 */
		adc1: adc@40012400 {
			compatible = "st,stm32-adc";                               /* in zephyr/dts/arm/st/f0/stm32f0.dtsi:347 */
			reg = < 0x40012400 0x400 >;                                /* in zephyr/dts/arm/st/f0/stm32f0.dtsi:348 */
			clocks = < &rcc 0x18 0x200 >;                              /* in zephyr/dts/arm/st/f0/stm32f0.dtsi:349 */
			clock-names = "adcx";                                      /* in zephyr/dts/arm/st/f0/stm32f0.dtsi:350 */
			interrupts = < 0xc 0x0 >;                                  /* in zephyr/dts/arm/st/f0/stm32f0.dtsi:351 */
			#io-channel-cells = < 0x1 >;                               /* in zephyr/dts/arm/st/f0/stm32f0.dtsi:352 */
			resolutions = < 0x60630c 0x51630c 0x42630c 0x33630c >;     /* in zephyr/dts/arm/st/f0/stm32f0.dtsi:353 */
			sampling-times = < 0x2 0x8 0xe 0x1d 0x2a 0x38 0x48 0xf0 >; /* in zephyr/dts/arm/st/f0/stm32f0.dtsi:357 */
			num-sampling-time-common-channels = < 0x1 >;               /* in zephyr/dts/arm/st/f0/stm32f0.dtsi:358 */
			st,adc-sequencer = "fixed";                                /* in zephyr/dts/arm/st/f0/stm32f0.dtsi:359 */
			st,adc-oversampler = "none";                               /* in zephyr/dts/arm/st/f0/stm32f0.dtsi:360 */
			st,adc-internal-regulator = "none";                        /* in zephyr/dts/arm/st/f0/stm32f0.dtsi:361 */
			pinctrl-0 = < &adc_in0_pa0 >;                              /* in zephyr/boards/st/nucleo_f030r8/nucleo_f030r8.dts:126 */
			pinctrl-names = "default";                                 /* in zephyr/boards/st/nucleo_f030r8/nucleo_f030r8.dts:127 */
			st,adc-clock-source = "SYNC";                              /* in zephyr/boards/st/nucleo_f030r8/nucleo_f030r8.dts:128 */
			st,adc-prescaler = < 0x4 >;                                /* in zephyr/boards/st/nucleo_f030r8/nucleo_f030r8.dts:129 */
			status = "okay";                                           /* in zephyr/boards/st/nucleo_f030r8/nucleo_f030r8.dts:130 */
			phandle = < 0x17 >;                                        /* in zephyr/dts/arm/st/f0/stm32f0.dtsi:379 */
		};

		/* node '/soc/dma@40020000' defined in zephyr/dts/arm/st/f0/stm32f0.dtsi:365 */
		dma1: dma@40020000 {
			compatible = "st,stm32-dma-v2bis";                        /* in zephyr/dts/arm/st/f0/stm32f0.dtsi:366 */
			#dma-cells = < 0x2 >;                                     /* in zephyr/dts/arm/st/f0/stm32f0.dtsi:367 */
			reg = < 0x40020000 0x400 >;                               /* in zephyr/dts/arm/st/f0/stm32f0.dtsi:368 */
			clocks = < &rcc 0x14 0x1 >;                               /* in zephyr/dts/arm/st/f0/stm32f0.dtsi:369 */
			interrupts = < 0x9 0x0 0xa 0x0 0xa 0x0 0xb 0x0 0xb 0x0 >; /* in zephyr/dts/arm/st/f0/stm32f0.dtsi:370 */
			status = "disabled";                                      /* in zephyr/dts/arm/st/f0/stm32f0.dtsi:371 */
		};

		/* node '/soc/serial@40004400' defined in zephyr/dts/arm/st/f0/stm32f030X8.dtsi:20 */
		usart2: serial@40004400 {
			compatible = "st,stm32-usart",
			             "st,stm32-uart";                  /* in zephyr/dts/arm/st/f0/stm32f030X8.dtsi:21 */
			reg = < 0x40004400 0x400 >;                    /* in zephyr/dts/arm/st/f0/stm32f030X8.dtsi:22 */
			clocks = < &rcc 0x1c 0x20000 >;                /* in zephyr/dts/arm/st/f0/stm32f030X8.dtsi:23 */
			resets = < &rctl 0x211 >;                      /* in zephyr/dts/arm/st/f0/stm32f030X8.dtsi:24 */
			interrupts = < 0x1c 0x0 >;                     /* in zephyr/dts/arm/st/f0/stm32f030X8.dtsi:25 */
			pinctrl-0 = < &usart2_tx_pa2 &usart2_rx_pa3 >; /* in zephyr/boards/st/nucleo_f030r8/nucleo_f030r8.dts:91 */
			pinctrl-names = "default";                     /* in zephyr/boards/st/nucleo_f030r8/nucleo_f030r8.dts:92 */
			current-speed = < 0x1c200 >;                   /* in zephyr/boards/st/nucleo_f030r8/nucleo_f030r8.dts:93 */
			status = "okay";                               /* in zephyr/boards/st/nucleo_f030r8/nucleo_f030r8.dts:94 */
		};

		/* node '/soc/i2c@40005800' defined in zephyr/dts/arm/st/f0/stm32f030X8.dtsi:29 */
		i2c2: i2c@40005800 {
			compatible = "st,stm32-i2c-v2";                /* in zephyr/dts/arm/st/f0/stm32f030X8.dtsi:30 */
			#address-cells = < 0x1 >;                      /* in zephyr/dts/arm/st/f0/stm32f030X8.dtsi:32 */
			#size-cells = < 0x0 >;                         /* in zephyr/dts/arm/st/f0/stm32f030X8.dtsi:33 */
			reg = < 0x40005800 0x400 >;                    /* in zephyr/dts/arm/st/f0/stm32f030X8.dtsi:34 */
			clocks = < &rcc 0x1c 0x400000 >;               /* in zephyr/dts/arm/st/f0/stm32f030X8.dtsi:35 */
			interrupts = < 0x18 0x0 >;                     /* in zephyr/dts/arm/st/f0/stm32f030X8.dtsi:36 */
			interrupt-names = "combined";                  /* in zephyr/dts/arm/st/f0/stm32f030X8.dtsi:37 */
			pinctrl-0 = < &i2c2_scl_pb10 &i2c2_sda_pb11 >; /* in zephyr/boards/st/nucleo_f030r8/nucleo_f030r8.dts:105 */
			pinctrl-names = "default";                     /* in zephyr/boards/st/nucleo_f030r8/nucleo_f030r8.dts:106 */
			status = "okay";                               /* in zephyr/boards/st/nucleo_f030r8/nucleo_f030r8.dts:107 */
			clock-frequency = < 0x61a80 >;                 /* in zephyr/boards/st/nucleo_f030r8/nucleo_f030r8.dts:108 */
			phandle = < 0x19 >;                            /* in zephyr/dts/arm/st/f0/stm32f030X8.dtsi:86 */
		};

		/* node '/soc/spi@40003800' defined in zephyr/dts/arm/st/f0/stm32f030X8.dtsi:41 */
		spi2: spi@40003800 {
			compatible = "st,stm32-spi-fifo",
			             "st,stm32-spi";                                                   /* in zephyr/dts/arm/st/f0/stm32f030X8.dtsi:42 */
			#address-cells = < 0x1 >;                                                      /* in zephyr/dts/arm/st/f0/stm32f030X8.dtsi:43 */
			#size-cells = < 0x0 >;                                                         /* in zephyr/dts/arm/st/f0/stm32f030X8.dtsi:44 */
			reg = < 0x40003800 0x400 >;                                                    /* in zephyr/dts/arm/st/f0/stm32f030X8.dtsi:45 */
			clocks = < &rcc 0x1c 0x4000 >;                                                 /* in zephyr/dts/arm/st/f0/stm32f030X8.dtsi:46 */
			interrupts = < 0x1a 0x3 >;                                                     /* in zephyr/dts/arm/st/f0/stm32f030X8.dtsi:47 */
			pinctrl-0 = < &spi2_nss_pb12 &spi2_sck_pb13 &spi2_miso_pb14 &spi2_mosi_pb15 >; /* in zephyr/boards/st/nucleo_f030r8/nucleo_f030r8.dts:119 */
			pinctrl-names = "default";                                                     /* in zephyr/boards/st/nucleo_f030r8/nucleo_f030r8.dts:121 */
			status = "okay";                                                               /* in zephyr/boards/st/nucleo_f030r8/nucleo_f030r8.dts:122 */
		};

		/* node '/soc/timers@40001000' defined in zephyr/dts/arm/st/f0/stm32f030X8.dtsi:51 */
		timers6: timers@40001000 {
			compatible = "st,stm32-timers"; /* in zephyr/dts/arm/st/f0/stm32f030X8.dtsi:52 */
			reg = < 0x40001000 0x400 >;     /* in zephyr/dts/arm/st/f0/stm32f030X8.dtsi:53 */
			clocks = < &rcc 0x1c 0x10 >,
			         < &rcc 0x8 0xff >;     /* in zephyr/dts/arm/st/f0/stm32f030X8.dtsi:54 */
			resets = < &rctl 0x204 >;       /* in zephyr/dts/arm/st/f0/stm32f030X8.dtsi:56 */
			interrupts = < 0x11 0x0 >;      /* in zephyr/dts/arm/st/f0/stm32f030X8.dtsi:57 */
			interrupt-names = "global";     /* in zephyr/dts/arm/st/f0/stm32f030X8.dtsi:58 */
			st,prescaler = < 0x0 >;         /* in zephyr/dts/arm/st/f0/stm32f030X8.dtsi:59 */
			status = "disabled";            /* in zephyr/dts/arm/st/f0/stm32f030X8.dtsi:60 */
		};

		/* node '/soc/timers@40014000' defined in zephyr/dts/arm/st/f0/stm32f030X8.dtsi:63 */
		timers15: timers@40014000 {
			compatible = "st,stm32-timers"; /* in zephyr/dts/arm/st/f0/stm32f030X8.dtsi:64 */
			reg = < 0x40014000 0x400 >;     /* in zephyr/dts/arm/st/f0/stm32f030X8.dtsi:65 */
			clocks = < &rcc 0x18 0x10000 >,
			         < &rcc 0x8 0xff >;     /* in zephyr/dts/arm/st/f0/stm32f030X8.dtsi:66 */
			resets = < &rctl 0x190 >;       /* in zephyr/dts/arm/st/f0/stm32f030X8.dtsi:68 */
			interrupts = < 0x14 0x0 >;      /* in zephyr/dts/arm/st/f0/stm32f030X8.dtsi:69 */
			interrupt-names = "global";     /* in zephyr/dts/arm/st/f0/stm32f030X8.dtsi:70 */
			st,prescaler = < 0x0 >;         /* in zephyr/dts/arm/st/f0/stm32f030X8.dtsi:71 */
			status = "disabled";            /* in zephyr/dts/arm/st/f0/stm32f030X8.dtsi:72 */

			/* node '/soc/timers@40014000/pwm' defined in zephyr/dts/arm/st/f0/stm32f030X8.dtsi:74 */
			pwm {
				compatible = "st,stm32-pwm"; /* in zephyr/dts/arm/st/f0/stm32f030X8.dtsi:75 */
				status = "disabled";         /* in zephyr/dts/arm/st/f0/stm32f030X8.dtsi:76 */
				#pwm-cells = < 0x3 >;        /* in zephyr/dts/arm/st/f0/stm32f030X8.dtsi:77 */
			};
		};
	};

	/* node '/cpus' defined in zephyr/dts/arm/st/f0/stm32f0.dtsi:27 */
	cpus {
		#address-cells = < 0x1 >; /* in zephyr/dts/arm/st/f0/stm32f0.dtsi:28 */
		#size-cells = < 0x0 >;    /* in zephyr/dts/arm/st/f0/stm32f0.dtsi:29 */

		/* node '/cpus/cpu@0' defined in zephyr/dts/arm/st/f0/stm32f0.dtsi:31 */
		cpu0: cpu@0 {
			device_type = "cpu";          /* in zephyr/dts/arm/st/f0/stm32f0.dtsi:32 */
			compatible = "arm,cortex-m0"; /* in zephyr/dts/arm/st/f0/stm32f0.dtsi:33 */
			reg = < 0x0 >;                /* in zephyr/dts/arm/st/f0/stm32f0.dtsi:34 */
		};
	};

	/* node '/memory@20000000' defined in zephyr/dts/arm/st/f0/stm32f0.dtsi:38 */
	sram0: memory@20000000 {
		compatible = "zephyr,memory-region",
		             "mmio-sram";            /* in zephyr/dts/arm/st/f0/stm32f0.dtsi:39 */
		zephyr,memory-region = "SRAM0";      /* in zephyr/dts/arm/st/f0/stm32f0.dtsi:40 */
		reg = < 0x20000000 0x2000 >;         /* in zephyr/dts/arm/st/f0/stm32f030X8.dtsi:10 */
	};

	/* node '/clocks' defined in zephyr/dts/arm/st/f0/stm32f0.dtsi:43 */
	clocks {

		/* node '/clocks/clk-hse' defined in zephyr/dts/arm/st/f0/stm32f0.dtsi:44 */
		clk_hse: clk-hse {
			#clock-cells = < 0x0 >;            /* in zephyr/dts/arm/st/f0/stm32f0.dtsi:45 */
			compatible = "st,stm32-hse-clock"; /* in zephyr/dts/arm/st/f0/stm32f0.dtsi:46 */
			hse-bypass;                        /* in zephyr/boards/st/nucleo_f030r8/nucleo_f030r8.dts:54 */
			clock-frequency = < 0x7a1200 >;    /* in zephyr/boards/st/nucleo_f030r8/nucleo_f030r8.dts:55 */
			status = "disabled";               /* in zephyr/boards/st/nucleo_f030r8/nucleo_f030r8_stm32f030x8_1.overlay:9 */
		};

		/* node '/clocks/clk-hsi' defined in zephyr/dts/arm/st/f0/stm32f0.dtsi:50 */
		clk_hsi: clk-hsi {
			#clock-cells = < 0x0 >;         /* in zephyr/dts/arm/st/f0/stm32f0.dtsi:51 */
			compatible = "fixed-clock";     /* in zephyr/dts/arm/st/f0/stm32f0.dtsi:52 */
			clock-frequency = < 0x7a1200 >; /* in zephyr/dts/arm/st/f0/stm32f0.dtsi:53 */
			status = "okay";                /* in zephyr/boards/st/nucleo_f030r8/nucleo_f030r8_stm32f030x8_1.overlay:13 */
			phandle = < 0x16 >;             /* in zephyr/boards/st/nucleo_f030r8/nucleo_f030r8_stm32f030x8_1.overlay:19 */
		};

		/* node '/clocks/clk-hsi14' defined in zephyr/dts/arm/st/f0/stm32f0.dtsi:57 */
		clk_hsi14: clk-hsi14 {
			#clock-cells = < 0x0 >;         /* in zephyr/dts/arm/st/f0/stm32f0.dtsi:58 */
			compatible = "fixed-clock";     /* in zephyr/dts/arm/st/f0/stm32f0.dtsi:59 */
			clock-frequency = < 0xd59f80 >; /* in zephyr/dts/arm/st/f0/stm32f0.dtsi:60 */
			status = "disabled";            /* in zephyr/dts/arm/st/f0/stm32f0.dtsi:61 */
		};

		/* node '/clocks/clk-lse' defined in zephyr/dts/arm/st/f0/stm32f0.dtsi:64 */
		clk_lse: clk-lse {
			#clock-cells = < 0x0 >;            /* in zephyr/dts/arm/st/f0/stm32f0.dtsi:65 */
			compatible = "st,stm32-lse-clock"; /* in zephyr/dts/arm/st/f0/stm32f0.dtsi:66 */
			clock-frequency = < 0x8000 >;      /* in zephyr/dts/arm/st/f0/stm32f0.dtsi:67 */
			driving-capability = < 0x0 >;      /* in zephyr/dts/arm/st/f0/stm32f0.dtsi:68 */
			status = "disabled";               /* in zephyr/dts/arm/st/f0/stm32f0.dtsi:69 */
		};

		/* node '/clocks/clk-lsi' defined in zephyr/dts/arm/st/f0/stm32f0.dtsi:72 */
		clk_lsi: clk-lsi {
			#clock-cells = < 0x0 >;       /* in zephyr/dts/arm/st/f0/stm32f0.dtsi:73 */
			compatible = "fixed-clock";   /* in zephyr/dts/arm/st/f0/stm32f0.dtsi:74 */
			clock-frequency = < 0x9c40 >; /* in zephyr/dts/arm/st/f0/stm32f0.dtsi:75 */
			status = "disabled";          /* in zephyr/dts/arm/st/f0/stm32f0.dtsi:76 */
		};

		/* node '/clocks/pll' defined in zephyr/dts/arm/st/f0/stm32f0.dtsi:79 */
		pll: pll {
			#clock-cells = < 0x0 >;              /* in zephyr/dts/arm/st/f0/stm32f0.dtsi:80 */
			compatible = "st,stm32f0-pll-clock"; /* in zephyr/dts/arm/st/f0/stm32f0.dtsi:81 */
			prediv = < 0x2 >;                    /* in zephyr/boards/st/nucleo_f030r8/nucleo_f030r8_stm32f030x8_1.overlay:17 */
			mul = < 0xc >;                       /* in zephyr/boards/st/nucleo_f030r8/nucleo_f030r8_stm32f030x8_1.overlay:18 */
			clocks = < &clk_hsi >;               /* in zephyr/boards/st/nucleo_f030r8/nucleo_f030r8_stm32f030x8_1.overlay:19 */
			status = "okay";                     /* in zephyr/boards/st/nucleo_f030r8/nucleo_f030r8_stm32f030x8_1.overlay:20 */
			phandle = < 0x3 >;                   /* in zephyr/boards/st/nucleo_f030r8/nucleo_f030r8.dts:67 */
		};
	};

	/* node '/vref' defined in zephyr/dts/arm/st/f0/stm32f0.dtsi:375 */
	vref: vref {
		compatible = "st,stm32-vref";      /* in zephyr/dts/arm/st/f0/stm32f0.dtsi:376 */
		vrefint-cal-addr = < 0x1ffff7ba >; /* in zephyr/dts/arm/st/f0/stm32f0.dtsi:377 */
		vrefint-cal-mv = < 0xce4 >;        /* in zephyr/dts/arm/st/f0/stm32f0.dtsi:378 */
		io-channels = < &adc1 0x11 >;      /* in zephyr/dts/arm/st/f0/stm32f0.dtsi:379 */
		status = "okay";                   /* in zephyr/boards/st/nucleo_f030r8/nucleo_f030r8.dts:142 */
	};

	/* node '/smbus1' defined in zephyr/dts/arm/st/f0/stm32f0.dtsi:383 */
	smbus1: smbus1 {
		compatible = "st,stm32-smbus"; /* in zephyr/dts/arm/st/f0/stm32f0.dtsi:384 */
		#address-cells = < 0x1 >;      /* in zephyr/dts/arm/st/f0/stm32f0.dtsi:385 */
		#size-cells = < 0x0 >;         /* in zephyr/dts/arm/st/f0/stm32f0.dtsi:386 */
		i2c = < &i2c1 >;               /* in zephyr/dts/arm/st/f0/stm32f0.dtsi:387 */
		status = "disabled";           /* in zephyr/dts/arm/st/f0/stm32f0.dtsi:388 */
	};

	/* node '/dietemp' defined in zephyr/dts/arm/st/f0/stm32f030.dtsi:14 */
	die_temp: dietemp {
		compatible = "st,stm32c0-temp-cal"; /* in zephyr/dts/arm/st/f0/stm32f030.dtsi:15 */
		ts-cal1-addr = < 0x1ffff7b8 >;      /* in zephyr/dts/arm/st/f0/stm32f030.dtsi:16 */
		ts-cal1-temp = < 0x1e >;            /* in zephyr/dts/arm/st/f0/stm32f030.dtsi:17 */
		ts-cal-vrefanalog = < 0xce4 >;      /* in zephyr/dts/arm/st/f0/stm32f030.dtsi:18 */
		avgslope = "4.3";                   /* in zephyr/dts/arm/st/f0/stm32f030.dtsi:19 */
		io-channels = < &adc1 0x10 >;       /* in zephyr/dts/arm/st/f0/stm32f030.dtsi:20 */
		ntc;                                /* in zephyr/dts/arm/st/f0/stm32f030.dtsi:21 */
		status = "okay";                    /* in zephyr/boards/st/nucleo_f030r8/nucleo_f030r8.dts:138 */
	};

	/* node '/smbus2' defined in zephyr/dts/arm/st/f0/stm32f030X8.dtsi:82 */
	smbus2: smbus2 {
		compatible = "st,stm32-smbus"; /* in zephyr/dts/arm/st/f0/stm32f030X8.dtsi:83 */
		#address-cells = < 0x1 >;      /* in zephyr/dts/arm/st/f0/stm32f030X8.dtsi:84 */
		#size-cells = < 0x0 >;         /* in zephyr/dts/arm/st/f0/stm32f030X8.dtsi:85 */
		i2c = < &i2c2 >;               /* in zephyr/dts/arm/st/f0/stm32f030X8.dtsi:86 */
		status = "disabled";           /* in zephyr/dts/arm/st/f0/stm32f030X8.dtsi:87 */
	};

	/* node '/connector' defined in zephyr/boards/st/nucleo_f030r8/arduino_r3_connector.dtsi:10 */
	arduino_header: connector {
		compatible = "arduino-header-r3";          /* in zephyr/boards/st/nucleo_f030r8/arduino_r3_connector.dtsi:11 */
		#gpio-cells = < 0x2 >;                     /* in zephyr/boards/st/nucleo_f030r8/arduino_r3_connector.dtsi:12 */
		gpio-map-mask = < 0xffffffff 0xffffffc0 >; /* in zephyr/boards/st/nucleo_f030r8/arduino_r3_connector.dtsi:13 */
		gpio-map-pass-thru = < 0x0 0x3f >;         /* in zephyr/boards/st/nucleo_f030r8/arduino_r3_connector.dtsi:14 */
		gpio-map = < 0x0 0x0 &gpioa 0x0 0x0 >,
		           < 0x1 0x0 &gpioa 0x1 0x0 >,
		           < 0x2 0x0 &gpioa 0x4 0x0 >,
		           < 0x3 0x0 &gpiob 0x0 0x0 >,
		           < 0x4 0x0 &gpioc 0x1 0x0 >,
		           < 0x5 0x0 &gpioc 0x0 0x0 >,
		           < 0x6 0x0 &gpioa 0x3 0x0 >,
		           < 0x7 0x0 &gpioa 0x2 0x0 >,
		           < 0x8 0x0 &gpioa 0xa 0x0 >,
		           < 0x9 0x0 &gpiob 0x3 0x0 >,
		           < 0xa 0x0 &gpiob 0x5 0x0 >,
		           < 0xb 0x0 &gpiob 0x4 0x0 >,
		           < 0xc 0x0 &gpiob 0xa 0x0 >,
		           < 0xd 0x0 &gpioa 0x8 0x0 >,
		           < 0xe 0x0 &gpioa 0x9 0x0 >,
		           < 0xf 0x0 &gpioc 0x7 0x0 >,
		           < 0x10 0x0 &gpiob 0x6 0x0 >,
		           < 0x11 0x0 &gpioa 0x7 0x0 >,
		           < 0x12 0x0 &gpioa 0x6 0x0 >,
		           < 0x13 0x0 &gpioa 0x5 0x0 >,
		           < 0x14 0x0 &gpiob 0x9 0x0 >,
		           < 0x15 0x0 &gpiob 0x8 0x0 >;    /* in zephyr/boards/st/nucleo_f030r8/arduino_r3_connector.dtsi:15 */
	};

	/* node '/st-morpho-header' defined in zephyr/boards/st/nucleo_f030r8/st_morpho_connector.dtsi:10 */
	st_morpho_header: st-morpho-header {
		compatible = "st-morpho-header";        /* in zephyr/boards/st/nucleo_f030r8/st_morpho_connector.dtsi:11 */
		#gpio-cells = < 0x2 >;                  /* in zephyr/boards/st/nucleo_f030r8/st_morpho_connector.dtsi:12 */
		gpio-map-mask = < 0xff 0x0 >;           /* in zephyr/boards/st/nucleo_f030r8/st_morpho_connector.dtsi:13 */
		gpio-map-pass-thru = < 0x0 0x7f >;      /* in zephyr/boards/st/nucleo_f030r8/st_morpho_connector.dtsi:14 */
		gpio-map = < 0x0 0x0 &gpioc 0xa 0x0 >,
		           < 0x1 0x0 &gpioc 0xb 0x0 >,
		           < 0x2 0x0 &gpioc 0xc 0x0 >,
		           < 0x3 0x0 &gpiod 0x2 0x0 >,
		           < 0x8 0x0 &gpiof 0x6 0x0 >,
		           < 0xa 0x0 &gpiof 0x7 0x0 >,
		           < 0xc 0x0 &gpioa 0xd 0x0 >,
		           < 0xe 0x0 &gpioa 0xe 0x0 >,
		           < 0x10 0x0 &gpioa 0xf 0x0 >,
		           < 0x14 0x0 &gpiob 0x7 0x0 >,
		           < 0x16 0x0 &gpioc 0xd 0x0 >,
		           < 0x18 0x0 &gpioc 0xe 0x0 >,
		           < 0x1a 0x0 &gpioc 0xf 0x0 >,
		           < 0x1b 0x0 &gpioa 0x0 0x0 >,
		           < 0x1c 0x0 &gpiof 0x0 0x0 >,
		           < 0x1d 0x0 &gpioa 0x1 0x0 >,
		           < 0x1e 0x0 &gpiof 0x1 0x0 >,
		           < 0x1f 0x0 &gpioa 0x4 0x0 >,
		           < 0x21 0x0 &gpiob 0x0 0x0 >,
		           < 0x22 0x0 &gpioc 0x2 0x0 >,
		           < 0x23 0x0 &gpioc 0x1 0x0 >,
		           < 0x24 0x0 &gpioc 0x3 0x0 >,
		           < 0x25 0x0 &gpioc 0x0 0x0 >,
		           < 0x48 0x0 &gpioc 0x9 0x0 >,
		           < 0x49 0x0 &gpioc 0x8 0x0 >,
		           < 0x4a 0x0 &gpiob 0x8 0x0 >,
		           < 0x4b 0x0 &gpioc 0x6 0x0 >,
		           < 0x4c 0x0 &gpiob 0x9 0x0 >,
		           < 0x4d 0x0 &gpioc 0x5 0x0 >,
		           < 0x52 0x0 &gpioa 0x5 0x0 >,
		           < 0x53 0x0 &gpioa 0xc 0x0 >,
		           < 0x54 0x0 &gpioa 0x6 0x0 >,
		           < 0x55 0x0 &gpioa 0xb 0x0 >,
		           < 0x56 0x0 &gpioa 0x7 0x0 >,
		           < 0x57 0x0 &gpiob 0xc 0x0 >,
		           < 0x58 0x0 &gpiob 0x6 0x0 >,
		           < 0x59 0x0 &gpiob 0xb 0x0 >,
		           < 0x5a 0x0 &gpioc 0x7 0x0 >,
		           < 0x5c 0x0 &gpioa 0x9 0x0 >,
		           < 0x5d 0x0 &gpiob 0x2 0x0 >,
		           < 0x5e 0x0 &gpioa 0x8 0x0 >,
		           < 0x5f 0x0 &gpiob 0x1 0x0 >,
		           < 0x60 0x0 &gpiob 0xa 0x0 >,
		           < 0x61 0x0 &gpiob 0xf 0x0 >,
		           < 0x62 0x0 &gpiob 0x4 0x0 >,
		           < 0x63 0x0 &gpiob 0xe 0x0 >,
		           < 0x64 0x0 &gpiob 0x5 0x0 >,
		           < 0x65 0x0 &gpiob 0xd 0x0 >,
		           < 0x66 0x0 &gpiob 0x3 0x0 >,
		           < 0x68 0x0 &gpioa 0xa 0x0 >,
		           < 0x69 0x0 &gpioc 0x4 0x0 >,
		           < 0x6a 0x0 &gpioa 0x2 0x0 >,
		           < 0x6b 0x0 &gpiof 0x5 0x0 >,
		           < 0x6c 0x0 &gpioa 0x3 0x0 >,
		           < 0x6d 0x0 &gpiof 0x4 0x0 >; /* in zephyr/boards/st/nucleo_f030r8/st_morpho_connector.dtsi:15 */
	};

	/* node '/leds' defined in zephyr/boards/st/nucleo_f030r8/nucleo_f030r8.dts:25 */
	leds: leds {
		compatible = "gpio-leds"; /* in zephyr/boards/st/nucleo_f030r8/nucleo_f030r8.dts:26 */

		/* node '/leds/led_2' defined in zephyr/boards/st/nucleo_f030r8/nucleo_f030r8.dts:28 */
		green_led_2: led_2 {
			gpios = < &gpioa 0x5 0x0 >; /* in zephyr/boards/st/nucleo_f030r8/nucleo_f030r8.dts:29 */
			label = "User LD2";         /* in zephyr/boards/st/nucleo_f030r8/nucleo_f030r8.dts:30 */
		};
	};

	/* node '/gpio_keys' defined in zephyr/boards/st/nucleo_f030r8/nucleo_f030r8.dts:34 */
	gpio_keys {
		compatible = "gpio-keys"; /* in zephyr/boards/st/nucleo_f030r8/nucleo_f030r8.dts:35 */

		/* node '/gpio_keys/button' defined in zephyr/boards/st/nucleo_f030r8/nucleo_f030r8.dts:37 */
		user_button: button {
			label = "User";             /* in zephyr/boards/st/nucleo_f030r8/nucleo_f030r8.dts:38 */
			gpios = < &gpioc 0xd 0x1 >; /* in zephyr/boards/st/nucleo_f030r8/nucleo_f030r8.dts:39 */
			zephyr,code = < 0xb >;      /* in zephyr/boards/st/nucleo_f030r8/nucleo_f030r8.dts:40 */
		};
	};
};
